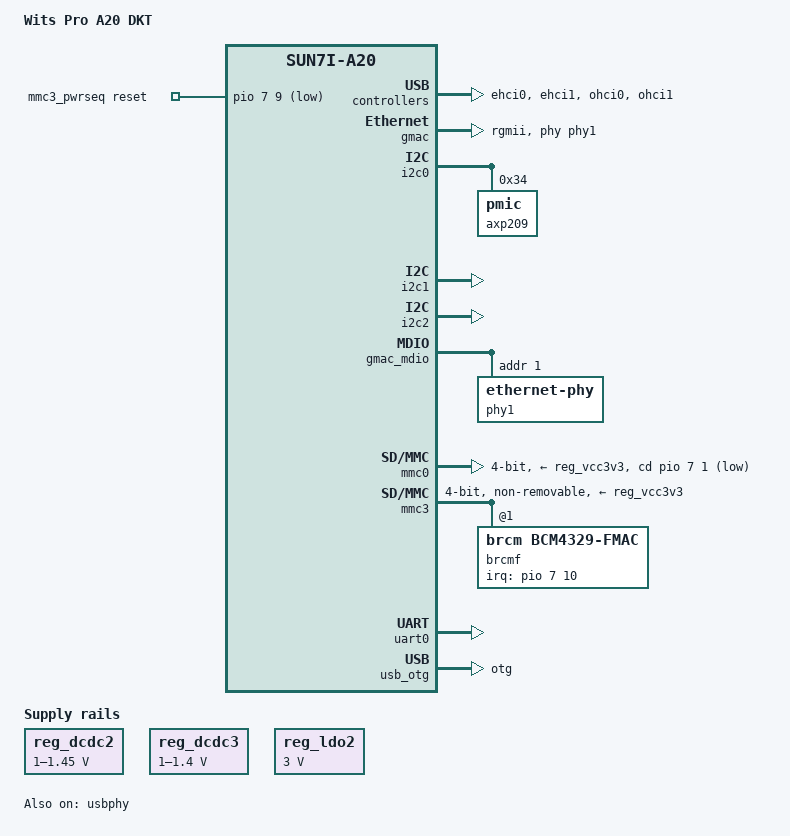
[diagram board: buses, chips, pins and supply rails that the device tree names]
/dts-v1/;
#include "sun7i-a20.dtsi"
#include "sunxi-common-regulators.dtsi"
#include <dt-bindings/gpio/gpio.h>
#include <dt-bindings/input/input.h>
#include <dt-bindings/interrupt-controller/irq.h>
/ {
	model = "Wits Pro A20 DKT";
	compatible = "wits,pro-a20-dkt", "allwinner,sun7i-a20";
	aliases {
		serial0 = &uart0;
	};
	chosen {
		stdout-path = "serial0:115200n8";
	};
	mmc3_pwrseq: mmc3_pwrseq {
		compatible = "mmc-pwrseq-simple";
		reset-gpios = <&pio 7 9 GPIO_ACTIVE_LOW>;  
	};
};
&cpu0 {
	cpu-supply = <&reg_dcdc2>;
};
&ehci0 {
	status = "okay";
};
&ehci1 {
	status = "okay";
};
&gmac {
	pinctrl-names = "default";
	pinctrl-0 = <&gmac_rgmii_pins>;
	phy-handle = <&phy1>;
	phy-mode = "rgmii";
	status = "okay";
};
&i2c0 {
	status = "okay";
	axp209: pmic@34 {
		reg = <0x34>;
		interrupt-parent = <&nmi_intc>;
		interrupts = <0 IRQ_TYPE_LEVEL_LOW>;
	};
};
&i2c1 {
	status = "okay";
};
&i2c2 {
	status = "okay";
};
#include "axp209.dtsi"
&gmac_mdio {
	phy1: ethernet-phy@1 {
		reg = <1>;
	};
};
&mmc0 {
	vmmc-supply = <&reg_vcc3v3>;
	bus-width = <4>;
	cd-gpios = <&pio 7 1 GPIO_ACTIVE_LOW>;  
	status = "okay";
};
&mmc3 {
	vmmc-supply = <&reg_vcc3v3>;
	mmc-pwrseq = <&mmc3_pwrseq>;
	bus-width = <4>;
	non-removable;
	status = "okay";
	brcmf: wifi@1 {
		reg = <1>;
		compatible = "brcm,bcm4329-fmac";
		interrupt-parent = <&pio>;
		interrupts = <7 10 IRQ_TYPE_LEVEL_LOW>;  
		interrupt-names = "host-wake";
	};
};
&ohci0 {
	status = "okay";
};
&ohci1 {
	status = "okay";
};
&otg_sram {
	status = "okay";
};
&reg_dcdc2 {
	regulator-always-on;
	regulator-min-microvolt = <1000000>;
	regulator-max-microvolt = <1450000>;
	regulator-name = "vdd-cpu";
};
&reg_dcdc3 {
	regulator-always-on;
	regulator-min-microvolt = <1000000>;
	regulator-max-microvolt = <1400000>;
	regulator-name = "vdd-int-dll";
};
&reg_ldo1 {
	regulator-name = "vdd-rtc";
};
&reg_ldo2 {
	regulator-always-on;
	regulator-min-microvolt = <3000000>;
	regulator-max-microvolt = <3000000>;
	regulator-name = "avcc";
};
&reg_usb0_vbus {
	status = "okay";
};
&reg_usb1_vbus {
	status = "okay";
};
&reg_usb2_vbus {
	status = "okay";
};
&uart0 {
	pinctrl-names = "default";
	pinctrl-0 = <&uart0_pb_pins>;
	status = "okay";
};
&usb_otg {
	dr_mode = "otg";
	status = "okay";
};
&usb_power_supply {
	status = "okay";
};
&usbphy {
	usb0_id_det-gpios = <&pio 7 4 (GPIO_ACTIVE_HIGH | GPIO_PULL_UP)>;  
	usb0_vbus_power-supply = <&usb_power_supply>;
	usb0_vbus-supply = <&reg_usb0_vbus>;
	usb1_vbus-supply = <&reg_usb1_vbus>;
	usb2_vbus-supply = <&reg_usb2_vbus>;
	status = "okay";
};
